# nrf54lv10a_enga_application register map
Vendor: Nordic Semiconductor; Series: nrf54l; File version: 1
CPU: CM33 r0p4, little endian, MPU, FPU, 3 interrupt priority bits, 270 interrupts, 4 SAU regions
Registers are 32-bit, read-write, reset 0x0 unless marked. A register's access mark holds for its fields unless they carry their own. Offsets are from the block's base; [hi:lo] are bit positions; lines under a group give offsets from that group; {n}, {i} and the like mark numbered series.

## GLOBAL_P1_NS — GPIO Port 0
Base 0x400D8200
Same registers: GLOBAL_P0_NS 0x4010A000, GLOBAL_P1_S 0x500D8200, GLOBAL_P0_S 0x5010A000
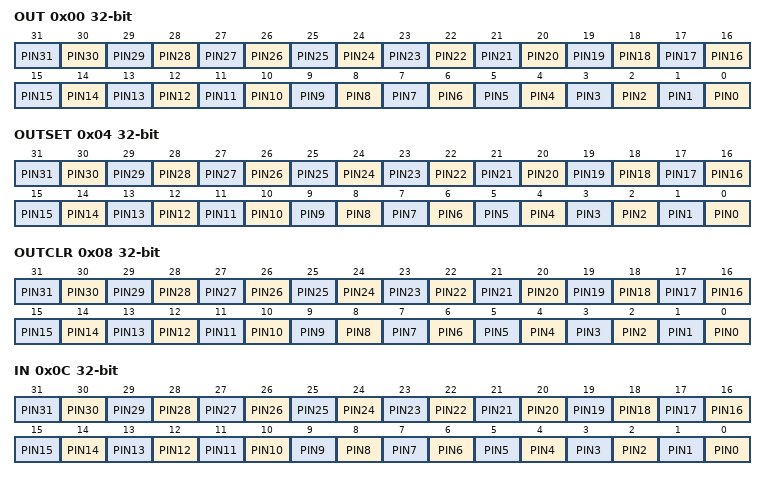
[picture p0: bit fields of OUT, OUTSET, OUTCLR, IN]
0x00 OUT — Write GPIO port
  [all] fields
    0=Low (Pin driver is low); 1=High (Pin driver is high)
  [n] PIN{n} (n=0..31)
0x04 OUTSET write-1-sets — Set individual bits in GPIO port
  [all] fields
    on read: 0=Low (Read: pin driver is low); 1=High (Read: pin driver is high) | on write: 1=Set (Write: writing a '1' sets the pin high; writing a '0' has no effect)
  [n] PIN{n} (n=0..31)
0x08 OUTCLR write-1-clears — Clear individual bits in GPIO port
  [all] fields
    on read: 0=Low (Read: pin driver is low); 1=High (Read: pin driver is high) | on write: 1=Clear (Write: writing a '1' sets the pin low; writing a '0' has no effect)
  [n] PIN{n} (n=0..31)
0x0C IN ro — Read GPIO port
  [all] fields
    0=Low (Pin input is low); 1=High (Pin input is high)
  [n] PIN{n} (n=0..31)
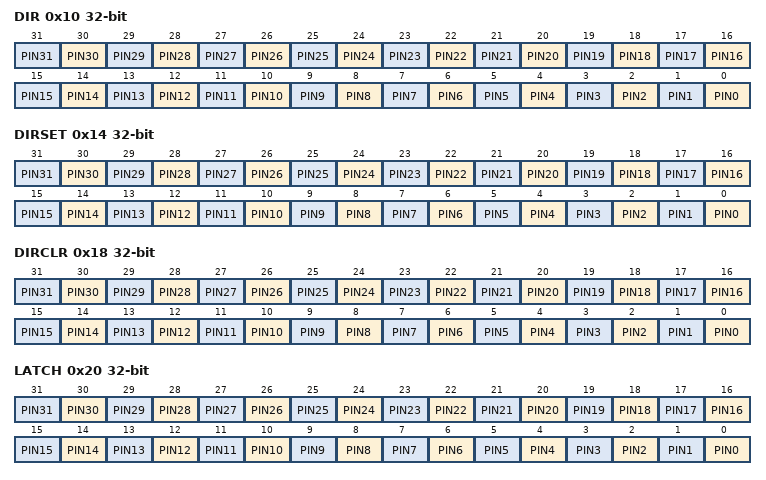
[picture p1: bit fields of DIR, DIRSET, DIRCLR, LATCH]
0x10 DIR — Direction of GPIO pins
  [all] fields
    0=Input (Pin set as input); 1=Output (Pin set as output)
  [n] PIN{n} (n=0..31)
0x14 DIRSET write-1-sets
  [all] fields
    on read: 0=Input (Read: pin set as input); 1=Output (Read: pin set as output) | on write: 1=Set (Write: writing a '1' sets pin to output; writing a '0' has no effect)
  [n] PIN{n} (n=0..31) — Set as output pin {n}
0x18 DIRCLR write-1-clears — DIR clear register
  [all] fields
    on read: 0=Input (Read: pin set as input); 1=Output (Read: pin set as output) | on write: 1=Clear (Write: writing a '1' sets pin to input; writing a '0' has no effect)
  [n] PIN{n} (n=0..31) — Set as input pin {n}
0x20 LATCH — Latch register indicating what GPIO pins that have met the criteria set in the PIN_CNF[n].SENSE registers
  [all] fields
    0=NotLatched (Criteria has not been met); 1=Latched (Criteria has been met)
  [n] PIN{n} (n=0..31) — Status on whether PIN{n} has met criteria set in PIN_CNF[{n}].SENSE register. Write '1' to clear.
0x24 DETECTMODE — Select between default DETECT signal behavior and LDETECT mode
  [0] DETECTMODE
    0=Default (DETECT directly connected to PIN DETECT signals); 1=LDETECT (Use the latched LDETECT behavior)
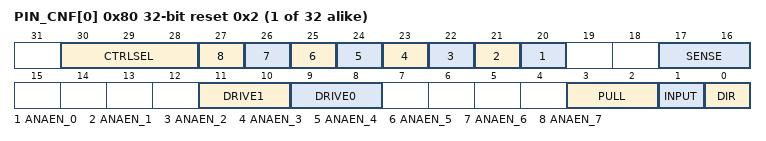
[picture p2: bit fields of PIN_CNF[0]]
{0x80+4i} PIN_CNF[{i}] (i=0..31) reset 0x2 — Description collection: Pin n configuration of GPIO pin
  [30:28] CTRLSEL — Select which module has direct control over this pin
    0=GPIO (GPIO or peripherals with PSEL registers); 1=VPR (VPR processor); 4=GRTC (GRTC peripheral)
  [n+20] ANAEN_{n} (n=0..7) — Control of analog slices for pads with ATB functionality. LSB in ANAEN control slice 0, and so on.
    0=Disabled (Slice disabled); 1=Enabled (Slice enabled)
  [17:16] SENSE — Pin sensing mechanism
    0=Disabled; 2=High (Sense for high level); 3=Low (Sense for low level)
  [11:10] DRIVE1 — Drive configuration for '1'
    0=S1 (Standard '1'); 1=H1 (High drive '1'); 2=D1 (Disconnect '1'(normally used for wired-or connections)); 3=E1 (Extra high drive '1')
  [9:8] DRIVE0 — Drive configuration for '0'
    0=S0 (Standard '0'); 1=H0 (High drive '0'); 2=D0 (Disconnect '0'(normally used for wired-or connections)); 3=E0 (Extra high drive '0')
  [3:2] PULL — Pull configuration
    0=Disabled (No pull); 1=Pull down on pin; 3=Pull up on pin
  [1] INPUT — Connect or disconnect input buffer
    0=Connect input buffer; 1=Disconnect input buffer
  [0] DIR — Pin direction. Same physical register as DIR register
    0=Input (Configure pin as an input pin); 1=Output (Configure pin as an output pin)

## GLOBAL_GPIOINTERNALP1_NS — GPIO Internal 0
Base 0x400D9E00
Same registers: GLOBAL_GPIOINTERNALP0_NS 0x4010BE00, GLOBAL_GPIOINTERNALP1_S 0x500D9E00, GLOBAL_GPIOINTERNALP0_S 0x5010BE00
0x40 LATCHCLRWAITCNT reset 0x2 — Select the number of wait cycles inserted on the bus when a LATCH register is cleared.
  [1:0] LATCHCLRWAITCNT
0x44 FORCELDETECTLOWCNT reset 0x8 — Select the number of cycles that LDETECT is forced low after clearing a LATCH register.
  [3:0] FORCELDETECTLOWCNT
0x48 RESET — Reset all GPIO registers.
  [0] RESET
    1=RESET (Trigger reset); 0=NA (No effect)
0x4C SENSECONFIGCHANGECNT reset 0x3 — Selects the number of cycles before the SENSE configuration takes effect when it is changed. Setting this register lower than the reset value can lead to unwanted LATCH set when SENSE and INPUT fields (PIN[n].CNF) are changed simultaneously.
  [2:0] SENSECONFIGCHANGECNT — Selects the number of cycles before the SENSE configuration takes effect when it is changed.
0x160 PCGC group — Unspecified
  {0x20+4j} PENALTY[{j}] (j=0..3) ro — Description collection: Penalty level for power/clock pair n
    [1:0] PENALTY — Penalty level
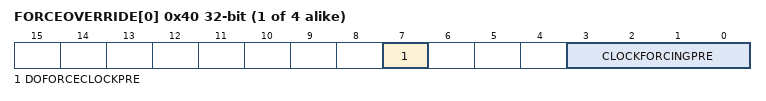
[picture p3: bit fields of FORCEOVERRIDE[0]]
  {0x40+4j} FORCEOVERRIDE[{j}] (j=0..3) ro — Description collection: Force override of power/clock pair n
    [7] DOFORCECLOCKPRE, [3:0] CLOCKFORCINGPRE
